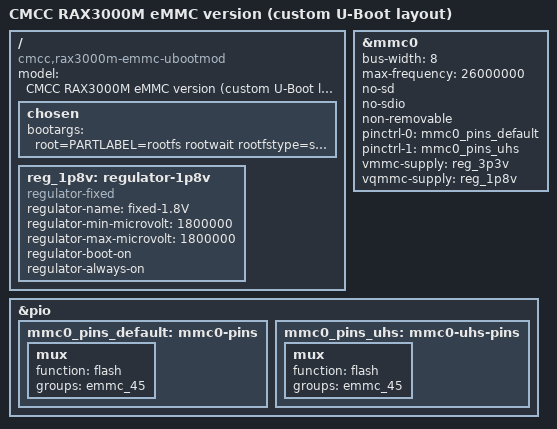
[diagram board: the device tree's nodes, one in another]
// SPDX-License-Identifier: GPL-2.0-or-later OR MIT

/dts-v1/;
#include "mt7981b-cmcc-rax3000m.dts"

/ {
	model = "CMCC RAX3000M eMMC version (custom U-Boot layout)";
	compatible = "cmcc,rax3000m-emmc-ubootmod", "mediatek,mt7981";

	chosen {
		bootargs = "root=PARTLABEL=rootfs rootwait rootfstype=squashfs,f2fs";
	};

	reg_1p8v: regulator-1p8v {
		compatible = "regulator-fixed";
		regulator-name = "fixed-1.8V";
		regulator-min-microvolt = <1800000>;
		regulator-max-microvolt = <1800000>;
		regulator-boot-on;
		regulator-always-on;
	};
};

&mmc0 {
	bus-width = <8>;
	max-frequency = <26000000>;
	no-sd;
	no-sdio;
	non-removable;
	pinctrl-names = "default", "state_uhs";
	pinctrl-0 = <&mmc0_pins_default>;
	pinctrl-1 = <&mmc0_pins_uhs>;
	vmmc-supply = <&reg_3p3v>;
	vqmmc-supply = <&reg_1p8v>;
	status = "okay";
};

&pio {
	mmc0_pins_default: mmc0-pins {
		mux {
			function = "flash";
			groups = "emmc_45";
		};
	};

	mmc0_pins_uhs: mmc0-uhs-pins {
		mux {
			function = "flash";
			groups = "emmc_45";
		};
	};
};
